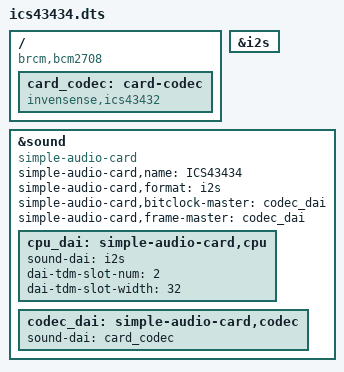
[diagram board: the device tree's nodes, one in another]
/dts-v1/;
/plugin/;

/ {
    compatible = "brcm,bcm2708";

    fragment@0 {
        target = <&i2s>;

        __overlay__ {
            status = "okay";
        };
    };

    fragment@1 {
        target-path = "/";

        __overlay__ {

            card_codec: card-codec {
                #sound-dai-cells = <0>;
                compatible = "invensense,ics43432";
                status = "okay";
            };
        };
    };

    fragment@2 {
        target = <&sound>;

        __overlay__ {

            compatible = "simple-audio-card";

            simple-audio-card,name = "ICS43434";
            simple-audio-card,format = "i2s";

            simple-audio-card,bitclock-master =
                <&codec_dai>;

            simple-audio-card,frame-master =
                <&codec_dai>;

            cpu_dai: simple-audio-card,cpu {
                sound-dai = <&i2s>;

                dai-tdm-slot-num = <2>;
                dai-tdm-slot-width = <32>;
            };

            codec_dai: simple-audio-card,codec {
                sound-dai = <&card_codec>;
            };
        };
    };
};
